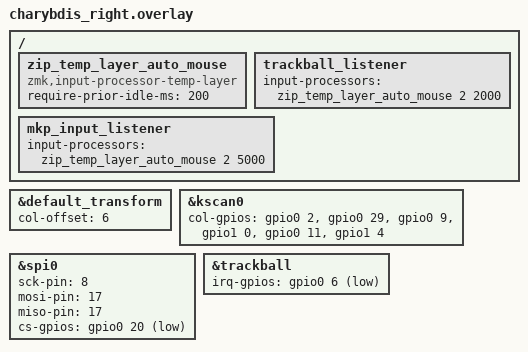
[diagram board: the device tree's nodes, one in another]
/*
 * Copyright (c) 2020 ZMK Contributors
 *
 * SPDX-License-Identifier: MIT
 */

#include "charybdis.dtsi"

/ {
    zip_temp_layer_auto_mouse: zip_temp_layer_auto_mouse {
        compatible = "zmk,input-processor-temp-layer";
        #input-processor-cells = <2>;
        require-prior-idle-ms = <200>;
    };

    trackball_listener {
        input-processors = <&zip_temp_layer_auto_mouse 2 2000>;
    };

    mkp_input_listener {
        input-processors = <&zip_temp_layer_auto_mouse 2 5000>;
    };
};

&default_transform {
    col-offset = <6>;
};

&kscan0 {
	col-gpios
		= <&gpio0 2 (GPIO_ACTIVE_HIGH | GPIO_PULL_DOWN)>
		, <&gpio0 29 (GPIO_ACTIVE_HIGH | GPIO_PULL_DOWN)>
		, <&gpio0 9 (GPIO_ACTIVE_HIGH | GPIO_PULL_DOWN)>
		, <&gpio1 0  (GPIO_ACTIVE_HIGH | GPIO_PULL_DOWN)>
		, <&gpio0 11 (GPIO_ACTIVE_HIGH | GPIO_PULL_DOWN)>
		, <&gpio1 4  (GPIO_ACTIVE_HIGH | GPIO_PULL_DOWN)>
		;
};

// trackball bus
&spi0 {
	status = "okay"; //okay
	sck-pin = <8>; //old
    mosi-pin = <17>; //old
    miso-pin = <17>;//old same as mosi (3-wire spi)
	cs-gpios = <&gpio0 20 GPIO_ACTIVE_LOW>;
};

&trackball {
	status = "okay"; //okay
	irq-gpios = <&gpio0 6 (GPIO_ACTIVE_LOW | GPIO_PULL_UP)>;
};
